# RS1xxxx register map
Vendor: Silicon Lab Inc.; Series: ARMCM4; File version: 1.2
CPU: CM4 r1p0, little endian, MPU, FPU, 6 interrupt priority bits
Registers are 32-bit, read-write, reset 0x0 unless marked. A register's access mark holds for its fields unless they carry their own. Offsets are from the block's base; [hi:lo] are bit positions; lines under a group give offsets from that group; {n}, {i} and the like mark numbered series; 'fields as' and 'values as' point back to an identical list.

## MCPWM — The Motor Control PWM (MCPWM) controller is used to generate a periodic pulse waveform, which is useful in motor control and power control applications
Base 0x47070000
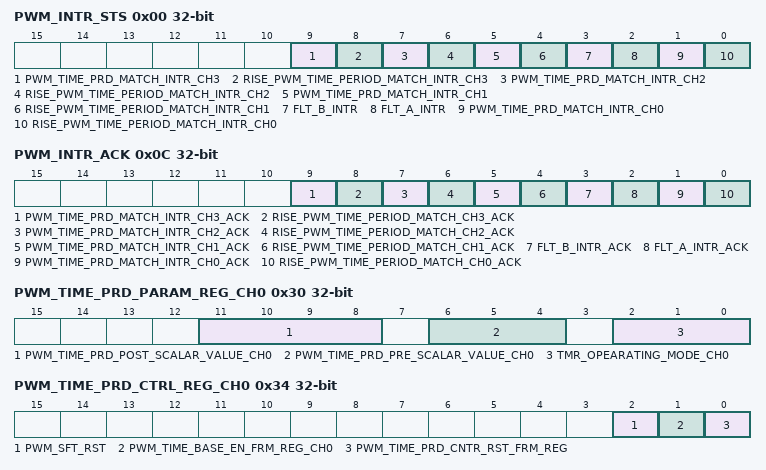
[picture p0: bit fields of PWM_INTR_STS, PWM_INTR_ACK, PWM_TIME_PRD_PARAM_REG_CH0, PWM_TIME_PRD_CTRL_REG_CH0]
0x00 PWM_INTR_STS ro — PWM Interrupt Status Register
  [9] PWM_TIME_PRD_MATCH_INTR_CH3 — This time base interrupt for 3rd channel, which considers postscaler value.
  [8] RISE_PWM_TIME_PERIOD_MATCH_INTR_CH3 — This time base interrupt for 3rd channel without considering postscaler value.
  [7] PWM_TIME_PRD_MATCH_INTR_CH2 — This time base interrupt for 2nd channel, which considers postscaler value
  [6] RISE_PWM_TIME_PERIOD_MATCH_INTR_CH2 — This time base interrupt for 2nd channel without considering postscaler value.
  [5] PWM_TIME_PRD_MATCH_INTR_CH1 — This time base interrupt for 1st channel, which considers postscaler value.
  [4] RISE_PWM_TIME_PERIOD_MATCH_INTR_CH1 — This time base interrupt for 1st channel without considering postscaler value
  [3] FLT_B_INTR — When the fault B pin is driven low, this interrupt is raised.
  [2] FLT_A_INTR — When the fault A pin is driven low, this interrupt is raised.
  [1] PWM_TIME_PRD_MATCH_INTR_CH0 — This time base interrupt for 0th channel, which considers postscaler value
  [0] RISE_PWM_TIME_PERIOD_MATCH_INTR_CH0 — This time base interrupt for 0th channel without considering postscaler
0x04 PWM_INTR_UNMASK — PWM Interrupt Unmask Register
  [15:0] PWM_INTR_UNMASK — Interrupt Unmask
0x08 PWM_INTR_MASK — PWM Interrupt mask Register
  [15:0] PWM_INTR_MASK — Interrupt Mask
0x0C PWM_INTR_ACK — PWM Interrupt Acknowledgement Register
  [9] PWM_TIME_PRD_MATCH_INTR_CH3_ACK wo — pwm time period match interrupt for 3rd channel will be cleared.
    0=Disable (No effect); 1=Enable (pwm time period match interrupt for 3rd channel will be cleared)
  [8] RISE_PWM_TIME_PERIOD_MATCH_CH3_ACK wo — pwm time period match interrupt for 3rd channel will be cleared.
    values as PWM_TIME_PRD_MATCH_INTR_CH3_ACK
  [7] PWM_TIME_PRD_MATCH_INTR_CH2_ACK wo — pwm time period match interrupt for 2nd channel will be cleared.
    0=Disable (No effect); 1=Enable (pwm time period match interrupt for 2nd channel will be cleared.)
  [6] RISE_PWM_TIME_PERIOD_MATCH_CH2_ACK wo — pwm time period match interrupt for 2nd channel will be cleared.
    0=Disable (No effect); 1=Enable (pwm time period match interrupt for 2nd channel will be cleared)
  [5] PWM_TIME_PRD_MATCH_INTR_CH1_ACK wo — pwm time period match interrupt for 1st channel will be cleared.
    0=Disable (No effect); 1=Enable (pwm time period match interrupt for 1st channel will be cleared.)
  [4] RISE_PWM_TIME_PERIOD_MATCH_CH1_ACK wo — pwm time period match interrupt for 1st channel will be cleared
    0=Disable (No effect); 1=Enable (pwm time period match interrupt for 1st channel will be cleared)
  [3] FLT_B_INTR_ACK wo — pwm fault B interrupt will be cleared.
    0=Disable (No effect); 1=Enable (pwm faultB interrupt will be cleared.)
  [2] FLT_A_INTR_ACK wo — pwm fault A interrupt will be cleared.
    0=Disable (No effect); 1=Enable (pwm faultA interrupt will be cleared)
  [1] PWM_TIME_PRD_MATCH_INTR_CH0_ACK wo — pwm time period match interrupt for 0th channel will be cleared
    0=Disable (No effect); 1=Enable (pwm time period match interrupt for 0th channel will be cleared)
  [0] RISE_PWM_TIME_PERIOD_MATCH_CH0_ACK wo — pwm time period match interrupt for 0th channel will be cleared.
    0=Disable (No effect.); 1=Enable (PWM time period match interrupt for 0th channel will be cleared.)
0x28 PWM_TIME_PRD_WR_REG_CH0 — Base timer period register of channel 0
  [15:0] PWM_TIME_PRD_REG_WR_VALUE_CH0 — Value to update the base timer period register of channel 0
0x2C PWM_TIME_PRD_CNTR_WR_REG_CH0 — Base time counter initial value register for channel 0
  [15:0] PWM_TIME_PRD_CNTR_WR_REG_CH0 — To update the base time counter initial value for channel 0
0x30 PWM_TIME_PRD_PARAM_REG_CH0 — Base time period config parameter's register for channel0
  [11:8] PWM_TIME_PRD_POST_SCALAR_VALUE_CH0 — Time base output post scale bits for channel0
    0=[1:1]_POST_SCALE (0000 1 to 1 post scale); 1=[1:2]_POST_SCALE (0001 1 to 2); 2=[1:3]_POST_SCALE (0010 1 to 3); 3=[1:4]_POST_SCALE (0011 1 to 4); 4=[1:5]_POST_SCALE (0100 1 to 5); 5=[1:6]_POST_SCALE (0101 1 to 6); 6=[1:7]_POST_SCALE (0110 1 to 7); 7=[1:8]_POST_SCALE (0111 1 to 8); 8=[1:9]_POST_SCALE (1000 1 to 9); 9=[1:10]_POST_SCALE (1001 1 to 10); 10=[1:11]_POST_SCALE (1010 1 to 11); 11=[1:12]_POST_SCALE (1011 [1:12]); 12=[1:13]_POST_SCALE (1100 [1:13]); 13=[1:14]_POST_SCALE (1101 1 to 14); 14=[1:15]_POST_SCALE (1110 1 to 15); 15=[1:16]_POST_SCALE (1111 1 to 16)
  [6:4] PWM_TIME_PRD_PRE_SCALAR_VALUE_CH0 — Base timer input clock pre scale select value for channel0.
    0=1X_CLOCK_PERIOD (1x input clock period); 1=2X_CLOCK_PERIOD (2x input clock period); 2=4X_CLOCK_PERIOD (4x input clock period); 3=16X_CLOCK_PERIOD (16x input clock period); 4=32X_CLOCK_PERIOD (32x input clock period); 5=NONE1; 6=64X_CLOCK_PERIOD (64x input clock period); 7=NONE2
  [2:0] TMR_OPEARATING_MODE_CH0 — Base timer operating mode for channel0
    0=FREE_RUNNING_MODE; 1=SINGLE_EVENT_MODE; 2=DOWN_COUNT_MODE; 3=NONE1; 4=UP_DOWN_MODE; 5=UP_DOWN_DOUBLER_MODE (up/down mode with interrupts for double PWM updates); 6=NONE2; 7=NONE3
0x34 PWM_TIME_PRD_CTRL_REG_CH0 — Base time counter initial value register for channel 0
  [2] PWM_SFT_RST — MC PWM soft reset
  [1] PWM_TIME_BASE_EN_FRM_REG_CH0 — Base timer enable for channnel0
    0=Disable (timer is disabled); 1=Enable (timer is enabled)
  [0] PWM_TIME_PRD_CNTR_RST_FRM_REG — Time period counter soft reset
0x38 PWM_TIME_PRD_STS_REG_CH0 ro — Base time period status register for channel0
  [0] PWM_TIME_PRD_DIR_STS_CH0 — Time period counter direction status for channel0
    0=Downward (Time period counter direction is downward); 1=Upward (Time period counter direction is upward)
0x3C PWM_TIME_PRD_CNTR_VALUE_CH0 ro — Base Time period counter current value register for channel0
  [15:0] PWM_TIME_PRD_CNTR_VALUE_CH0 — Time period counter current value for channel0
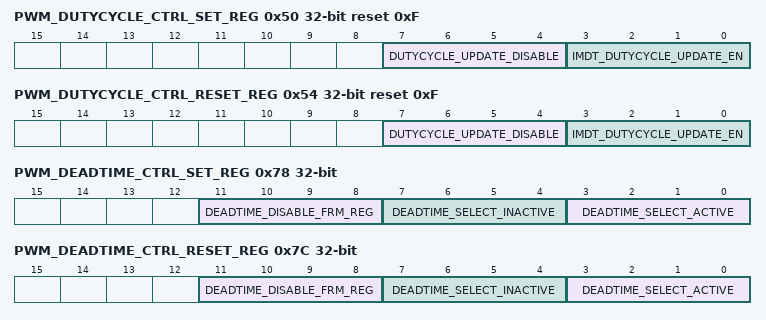
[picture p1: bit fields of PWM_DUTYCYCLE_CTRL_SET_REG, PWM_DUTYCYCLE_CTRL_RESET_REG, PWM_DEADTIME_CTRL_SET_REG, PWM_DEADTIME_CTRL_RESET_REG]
0x50 PWM_DUTYCYCLE_CTRL_SET_REG reset 0xF — Duty cycle Control Set Register
  [7:4] DUTYCYCLE_UPDATE_DISABLE — Duty cycle register updation disable. There is a separate bit for each channel
  [3:0] IMDT_DUTYCYCLE_UPDATE_EN — Enable to update the duty cycle immediately
0x54 PWM_DUTYCYCLE_CTRL_RESET_REG reset 0xF — Duty cycle Control Reset Register
  [7:4] DUTYCYCLE_UPDATE_DISABLE — Duty cycle register updation disable. There is a separate bit for each channel.
  [3:0] IMDT_DUTYCYCLE_UPDATE_EN — Enable to update the duty cycle immediately
{0x58+4i} PWM_DUTYCYCLE_REG_WR_VALUEn[{i}] (i=0..3) group — Duty cycle Value Register for Channel 0 to channel 3
  0x00 PWM_DUTYCYCLE_REG_WR_VALUE__n_ — Duty cycle Value Register for Channel
    [15:0] PWM_DUTYCYCLE_REG_WR_VALUE_CH_n_ — Duty cycle value for channel0 to channel3
0x78 PWM_DEADTIME_CTRL_SET_REG — Dead time Control Set Register
  [11:8] DEADTIME_DISABLE_FRM_REG — Dead time counter soft reset for each channel.
  [7:4] DEADTIME_SELECT_INACTIVE — Dead time select bits for PWM going inactive
    0=Disable (means use counter A); 1=Enable (means use counter B)
  [3:0] DEADTIME_SELECT_ACTIVE — Dead time select bits for PWM going active
    values as DEADTIME_SELECT_INACTIVE
0x7C PWM_DEADTIME_CTRL_RESET_REG — Dead time Control Reset Register
  fields as PWM_DEADTIME_CTRL_SET_REG
0x80 PWM_DEADTIME_PRESCALE_SELECT_A (reset mask 0xF) — Dead time Prescale Select Register for A
  [7:0] DEADTIME_PRESCALE_SELECT_A — Dead time prescale selection bits for unit A.
0x84 PWM_DEADTIME_PRESCALE_SELECT_B (reset mask 0xF) — Dead time Prescale Select Register for B
  [7:0] DEADTIME_PRESCALE_SELECT_B — Dead time prescale selection bits for unit B
{0x88+8i} PWM_DEADTIMEn[{i}] (i=0..3) group — PWM_DEADTIME_A (0-3) and PWM_DEADTIME_B (0-3)
  0x00 PWM_DEADTIME_A__n_ — PWM deadtime for A and channel varies from 0 to 3
    [5:0] DEADTIME_A_CH_n_ — Dead time A value to load into dead time counter A of channel0 to channel3
  0x04 PWM_DEADTIME_B__n_ — PWM deadtime for B and channel varies from 0 to 3
    [5:0] DEADTIME_B_CH_n_ — Dead time B value to load into deadtime counter B of channel0 to channel3
0xC8 PWM_OP_OVERRIDE_CTRL_SET_REG — output override control set register
  [0] OP_OVERRIDE_SYNC — Output override is synced with pwm time period depending on operating mode
0xCC PWM_OP_OVERRIDE_CTRL_RESET_REG — output override control reset register
  fields as PWM_OP_OVERRIDE_CTRL_SET_REG
0xD0 PWM_OP_OVERRIDE_ENABLE_SET_REG — output override enable set register
  [7:0] PWM_OP_OVERRIDE_ENABLE_REG — Pwm output over ride enable
0xD4 PWM_OP_OVERRIDE_ENABLE_RESET_REG — output override enable reset register
  [7:0] PWM_OP_OVERRIDE_ENABLE_REG — Pwm output over ride enable
0xD8 PWM_OP_OVERRIDE_VALUE_SET_REG — output override value set register
  [7:0] OP_OVERRIDE_VALUE — Pwm output over ride value.
0xDC PWM_OP_OVERRIDE_VALUE_RESET_REG — output override enable reset register
  [7:0] OP_OVERRIDE_VALUE — Pwm output over ride value.
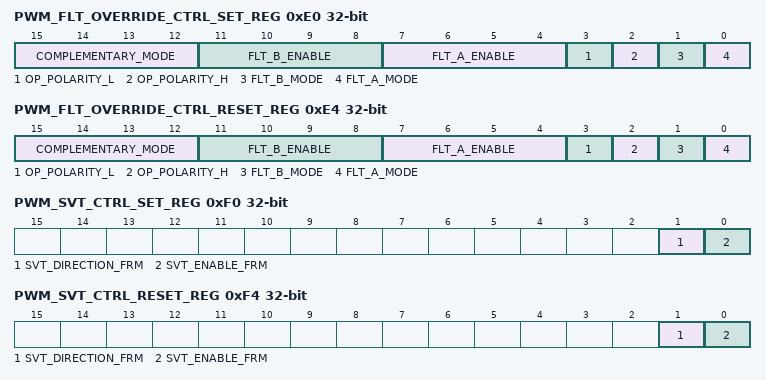
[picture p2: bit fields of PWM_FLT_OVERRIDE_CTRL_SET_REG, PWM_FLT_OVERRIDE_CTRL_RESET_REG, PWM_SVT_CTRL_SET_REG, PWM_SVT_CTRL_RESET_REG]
0xE0 PWM_FLT_OVERRIDE_CTRL_SET_REG — fault override control set register
  [15:12] COMPLEMENTARY_MODE — PWM I/O pair mode
    0=Disable (PWM I/O pin pair is in the independent output mode); 1=Enable (PWM I/O pin pair is in the complementary output mode)
  [11:8] FLT_B_ENABLE — Fault B enable. Separate enable bit is present for channel
  [7:4] FLT_A_ENABLE — Fault A enable. Separate enable bit is present for channel
  [3] OP_POLARITY_L — Ouput polarity for low (L3, L2, L1, L0) side signals.
    0=Disable (means active low mode); 1=Enable (means active high mode)
  [2] OP_POLARITY_H — Ouput polarity for high (H3, H2, H1, H0) side signals
    values as OP_POLARITY_L
  [1] FLT_B_MODE — Fault B mode
    0=Disable (latched mode); 1=Enable (cycle by cycle by mode)
  [0] FLT_A_MODE — Fault A mode
    0=Disable (latched mode); 1=Enable (cycle by cycle by mode)
0xE4 PWM_FLT_OVERRIDE_CTRL_RESET_REG (reset mask 0xFF) — fault override control reset register
  [15:12] COMPLEMENTARY_MODE — PWM I/O pair mode
    values as PWM_FLT_OVERRIDE_CTRL_SET_REG.COMPLEMENTARY_MODE
  [11:8] FLT_B_ENABLE — Fault B enable. Separate enable bit is present for channel
  [7:4] FLT_A_ENABLE — Fault A enable. Separate enable bit is present for channel
  [3] OP_POLARITY_L — Ouput polarity for low (L3, L2, L1, L0) side signals.
    values as PWM_FLT_OVERRIDE_CTRL_SET_REG.OP_POLARITY_L
  [2] OP_POLARITY_H — Ouput polarity for high (H3, H2, H1, H0) side signals
    values as PWM_FLT_OVERRIDE_CTRL_SET_REG.OP_POLARITY_L
  [1] FLT_B_MODE — Fault B mode
    0=Disable (latched mode); 1=Enable (cycle by cycle by mode)
  [0] FLT_A_MODE — Fault B mode
    0=Disable (latched mode); 1=Enable (cycle by cycle by mode)
0xE8 PWM_FLT_A_OVERRIDE_VALUE_REG — Fault input A PWM override value
  [7:0] PWM_FLT_A_OVERRIDE_VALUE_reg — 0 bit for L0,1-L1,2-L2,3-L3,4-L4,5-L5,6-L6,7-L7
    0=Inactive (0 means PWM output pin is driven inactive on an external fault input A event); 1=Active (1 means PWM output pin is driven active on an external fault input A event.)
0xEC PWM_FLT_B_OVERRIDE_VALUE_REG — Fault input B PWM override value
  [7:0] PWM_FLT_B_OVERRIDE_VALUE_reg — 0 bit for L0, 1-L1,2-L2,3-L3,4-L4,5-L5,6-L6,7-L7
    values as PWM_FLT_A_OVERRIDE_VALUE_REG.PWM_FLT_A_OVERRIDE_VALUE_reg
0xF0 PWM_SVT_CTRL_SET_REG
  [1] SVT_DIRECTION_FRM — Special event trigger for time base direction
    0=COUNT_UP (A special event trigger will occur when PWM time base is counting up); 1=COUNT_DOWN (A special event trigger will occur when PWM time base is counting down)
  [0] SVT_ENABLE_FRM — Special event trigger enable. This is used to enable generation special event trigger
0xF4 PWM_SVT_CTRL_RESET_REG — Special event control reset register
  fields as PWM_SVT_CTRL_SET_REG
0xF8 PWM_SVT_PARAM_REG — Special event parameter register
  [3:0] SVT_POSTSCALER_SELECT — PWM special event trigger output postscale select bits
0xFC PWM_SVT_COMPARE_VALUE_REG — Special event compare value register
  [15:0] PWM_SVT_COMPARE_VALUE — Special event compare value. This is used to compare with pwm time period counter to generate special event trigger
0x100 PWM_TIME_PRD_WR_REG_CH1 — Base timer period register of channel1
  [15:0] PWM_TIME_PRD_REG_WR_VALUE_CH1 — Value to update the base timer period register of channel 1
0x104 PWM_TIME_PRD_CNTR_WR_REG_CH1 — Base time counter initial value register for channel1
  [15:0] PWM_TIME_PRD_CNTR_WR_REG_CH1 — To update the base time counter initial value for channel 1
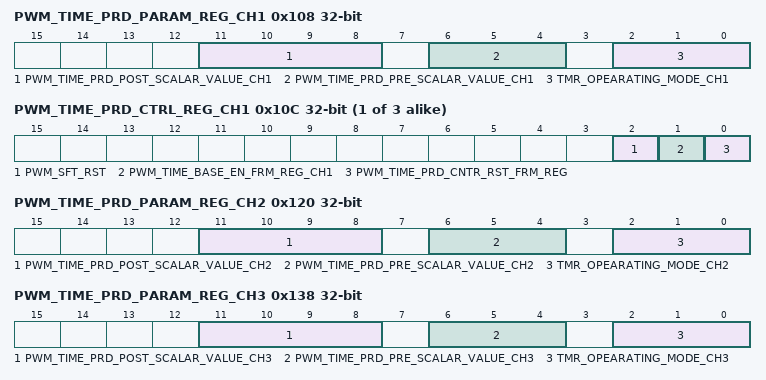
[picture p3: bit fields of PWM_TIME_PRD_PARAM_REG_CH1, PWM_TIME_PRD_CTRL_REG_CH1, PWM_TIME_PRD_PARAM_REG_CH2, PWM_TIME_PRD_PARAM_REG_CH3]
0x108 PWM_TIME_PRD_PARAM_REG_CH1 (reset mask 0xFF)
  [11:8] PWM_TIME_PRD_POST_SCALAR_VALUE_CH1 — Time base output post scale bits for channel1
    0=[1:1]_post_scale (0000 [1:1] post scale); 1=[1:2]_post_scale (0001 [1:2]); 2=[1:3]_post_scale (0010 [1:3]); 3=[1:4]_post_scale (0011 [1:4]); 4=[1:5]_post_scale (0100 [1:5]); 5=[1:6]_post_scale (0101 [1:6]); 6=[1:7]_post_scale (0110 [1:7]); 7=[1:8]_post_scale (0111 [1:8]); 8=[1:9]_post_scale (1000 [1:9]); 9=[1:10]_post_scale (1001 [1:10]); 10=[1:11]_post_scale (1010 [1:11]); 11=[1:12]_post_scale (1011 [1:12]); 12=[1:13]_post_scale (1100 [1:13]); 13=[1:14]_post_scale (1101 [1:14]); 14=[1:15]_post_scale (1110 [1:15]); 15=[1:16]_post_scale (1111 [1:16])
  [6:4] PWM_TIME_PRD_PRE_SCALAR_VALUE_CH1 — Base timer input clock prescale select value for channel1.
    0=1x_clock_period (1x input clock period); 1=2x_clock_period (2x input clock period); 2=4x_clock_period (4x input clock period); 3=16x_clock_period (16x input clock period); 4=32x_clock_period (32x input clock period); 5=NONE1 (none2); 6=64x_clock_period (64x input clock period); 7=NONE2 (none1)
  [2:0] TMR_OPEARATING_MODE_CH1 — Base timer operating mode for channel1
    0=FREE_RUNNING_MODE; 1=SINGLE_EVENT_MODE; 2=DOWN_COUNT_MODE; 3=NONE1; 4=UP_DOWN_MODE; 5=UP_DOWN_DOUBLER_MODE (up/dowm mode with interrupts for double PWM updates); 6=NONE2; 7=NONE3
{0xF4+0x18*i} PWM_TIME_PRD_CTRL_REG_CH{i} (i=1..3) — Base time period control register for channel{i}
  [2] PWM_SFT_RST — MC PWM soft reset
  [1] PWM_TIME_BASE_EN_FRM_REG_CH{i} — Base timer enable for channnel{i}
    0=Disable (timer is disabled); 1=Enable (timer is enabled)
  [0] PWM_TIME_PRD_CNTR_RST_FRM_REG — Time period counter soft reset
0x110 PWM_TIME_PRD_STS_REG_CH1 ro — Base time period status register for channel1
  [0] PWM_TIME_PRD_DIR_STS_CH1 — Time period counter direction status for channel1.
    0=Downward; 1=Upward
0x114 PWM_TIME_PRD_CNTR_VALUE_CH1 ro — Time period counter current value for channel1
  [15:0] PWM_TIME_PRD_CNTR_VALUE_CH1
0x118 PWM_TIME_PRD_WR_REG_CH2 — Base timer period register of channel2
  [15:0] PWM_TIME_PRD_REG_WR_VALUE_CH2 — Value to update the base timer period register of channel 2
0x11C PWM_TIME_PRD_CNTR_WR_REG_CH2 — Base time counter initial value register for channal2
  [15:0] PWM_TIME_PRD_CNTR_WR_REG_CH2 — To update the base time counter initial value for channel 2
0x120 PWM_TIME_PRD_PARAM_REG_CH2 — Base time period config parameter's register for channel2
  [11:8] PWM_TIME_PRD_POST_SCALAR_VALUE_CH2 — Time base output post scale bits for channel2
    0=[1:1]_POST_SCALE (0000 [1:1] post scale); 1=[1:2]_POST_SCALE (0001 [1:2]); 2=[1:3]_POST_SCALE (0010 [1:3]); 3=[1:4]_POST_SCALE (0011 [1:4]); 4=[1:5]_POST_SCALE (0100 [1:5]); 5=[1:6]_POST_SCALE (0101 [1:6]); 6=[1:7]_POST_SCALE (0110 [1:7]); 7=[1:8]_POST_SCALE (0111 [1:8]); 8=[1:9]_POST_SCALE (1000 [1:9]); 9=[1:10]_POST_SCALE (1001 [1:10]); 10=[1:11]_POST_SCALE (1010 [1:11]); 11=[1:12]_POST_SCALE (1011 [1:12]); 12=[1:13]_POST_SCALE (1100 [1:13]); 13=[1:14]_POST_SCALE (1101 [1:14]); 14=[1:15]_POST_SCALE (1110 [1:15]); 15=[1:16]_POST_SCALE (1111 [1:16])
  [6:4] PWM_TIME_PRD_PRE_SCALAR_VALUE_CH2 — Base timer input clock pre scale select value for channel2.
    values as PWM_TIME_PRD_PARAM_REG_CH0.PWM_TIME_PRD_PRE_SCALAR_VALUE_CH0
  [2:0] TMR_OPEARATING_MODE_CH2 — Base timer operating mode for channel2
    values as PWM_TIME_PRD_PARAM_REG_CH0.TMR_OPEARATING_MODE_CH0
0x128 PWM_TIME_PRD_STS_REG_CH2 ro — Base time period status register for channel2
  [0] PWM_TIME_PRD_DIR_STS_CH2 — Time period counter direction status for channel2.
    0=Downward; 1=Upward
0x12C PWM_TIME_PRD_CNTR_VALUE_CH2 ro (reset mask 0x1) — Time period counter current value register for channel2
  [15:0] PWM_TIME_PRD_CNTR_VALUE_CH2 — Time period counter current value for channel2
0x130 PWM_TIME_PRD_WR_REG_CH3 — Base timer period register of channel3
  [15:0] PWM_TIME_PRD_REG_WR_VALUE_CH3 — To update the base time counter initial value for channel 3
0x134 PWM_TIME_PRD_CNTR_WR_REG_CH3 — Base time counter initial value register for channel3
  [15:0] PWM_TIME_PRD_CNTR_WR_REG_CH3 — Value to update the base timer period register of channel 3
0x138 PWM_TIME_PRD_PARAM_REG_CH3 — Base time period config parameter's register for channel3
  [11:8] PWM_TIME_PRD_POST_SCALAR_VALUE_CH3 — Time base output post scale bits for channel3
    values as PWM_TIME_PRD_PARAM_REG_CH2.PWM_TIME_PRD_POST_SCALAR_VALUE_CH2
  [6:4] PWM_TIME_PRD_PRE_SCALAR_VALUE_CH3 — Base timer input clock pre scale select value for channel2.
    values as PWM_TIME_PRD_PARAM_REG_CH0.PWM_TIME_PRD_PRE_SCALAR_VALUE_CH0
  [2:0] TMR_OPEARATING_MODE_CH3 — Base timer operating mode for channel3
    0=FREE_RUNNING_MODE; 1=SINGLE_EVENT_MODE; 2=DOWN_COUNT_MODE; 3=NONE1; 4=UP_DOWN_MODE; 5=DOUBLE_PWM_UPDATES (up/down mode with interrupts for double PWM updates); 6=NONE2; 7=NONE3
0x140 PWM_TIME_PRD_STS_REG_CH3 ro — Base time period status register for channel3
  [0] PWM_TIME_PRD_DIR_STS_CH3 — Time period counter direction status for channel3.
    0=downward; 1=upward
0x144 PWM_TIME_PRD_CNTR_VALUE_CH3 ro (reset mask 0x1) — Time period counter current value register for channel3
  [15:0] PWM_TIME_PRD_CNTR_VALUE_CH3 — Time period counter current value for channe3
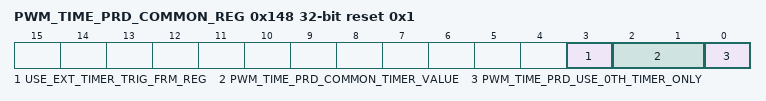
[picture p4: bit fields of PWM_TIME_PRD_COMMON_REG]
0x148 PWM_TIME_PRD_COMMON_REG reset 0x1 (reset mask 0x1) — Time period common register
  [3] USE_EXT_TIMER_TRIG_FRM_REG — Enable to use external trigger for base time counter increment or decrement.
  [2:1] PWM_TIME_PRD_COMMON_TIMER_VALUE — Base timers select to generate special event trigger
  [0] PWM_TIME_PRD_USE_0TH_TIMER_ONLY — Instead of use four base timers for four channels, use only one base timer for all channels.
    0=ONE_TIMER_ONE_CHANNEL (one base timer for each channel); 1=ONE_TIMER_ALL_CHANNEL (only one base timer for all channels)
